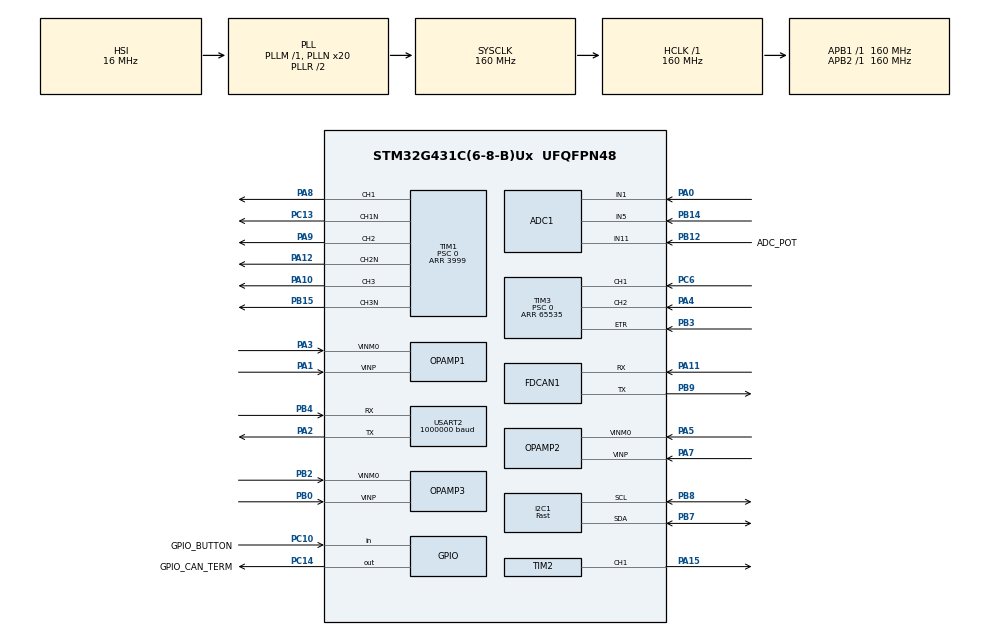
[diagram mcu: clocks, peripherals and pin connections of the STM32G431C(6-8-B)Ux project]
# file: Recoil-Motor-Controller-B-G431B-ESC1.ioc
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ADC1.DMAContinuousRequests=DISABLE
ADC1.EOCSelection=ADC_EOC_SEQ_CONV
ADC1.EnableInjectedConversion=ENABLE
ADC1.EnableRegularConversion=DISABLE
ADC1.ExternalTrigInjecConv=ADC_EXTERNALTRIGINJEC_T1_TRGO
ADC1.InjNumberOfConversion=3
ADC1.InjectedChannel-13\#ChannelInjectedConversion=ADC_CHANNEL_1
ADC1.InjectedChannel-14\#ChannelInjectedConversion=ADC_CHANNEL_11
ADC1.InjectedChannel-8\#ChannelInjectedConversion=ADC_CHANNEL_VOPAMP1
ADC1.InjectedConvMode=None
ADC1.InjectedOffsetNumber-13\#ChannelInjectedConversion=ADC_OFFSET_NONE
ADC1.InjectedOffsetNumber-14\#ChannelInjectedConversion=ADC_OFFSET_NONE
ADC1.InjectedOffsetNumber-8\#ChannelInjectedConversion=ADC_OFFSET_NONE
ADC1.InjectedRank-13\#ChannelInjectedConversion=2
ADC1.InjectedRank-14\#ChannelInjectedConversion=3
ADC1.InjectedRank-8\#ChannelInjectedConversion=1
ADC1.InjectedSamplingTime-13\#ChannelInjectedConversion=ADC_SAMPLETIME_2CYCLES_5
ADC1.InjectedSamplingTime-14\#ChannelInjectedConversion=ADC_SAMPLETIME_2CYCLES_5
ADC1.InjectedSamplingTime-8\#ChannelInjectedConversion=ADC_SAMPLETIME_2CYCLES_5
ADC1.Overrun=ADC_OVR_DATA_OVERWRITTEN
ADC1.Rank1_Channel=ADC_CHANNEL_VOPAMP1
ADC1.Rank2_Channel=ADC_CHANNEL_1
ADC1.Rank3_Channel=ADC_CHANNEL_11
ADC1.master=1
ADC2.DMAContinuousRequests=DISABLE
ADC2.EOCSelection=ADC_EOC_SEQ_CONV
ADC2.EnableInjectedConversion=ENABLE
ADC2.EnableRegularConversion=DISABLE
ADC2.ExternalTrigInjecConv=ADC_EXTERNALTRIGINJEC_T1_TRGO
ADC2.InjNumberOfConversion=2
ADC2.InjectedChannel-4\#ChannelInjectedConversion=ADC_CHANNEL_VOPAMP2
ADC2.InjectedChannel-5\#ChannelInjectedConversion=ADC_CHANNEL_VOPAMP3_ADC2
ADC2.InjectedConvMode=None
ADC2.InjectedOffsetNumber-4\#ChannelInjectedConversion=ADC_OFFSET_NONE
ADC2.InjectedOffsetNumber-5\#ChannelInjectedConversion=ADC_OFFSET_NONE
ADC2.InjectedRank-4\#ChannelInjectedConversion=1
ADC2.InjectedRank-5\#ChannelInjectedConversion=2
ADC2.InjectedSamplingTime-4\#ChannelInjectedConversion=ADC_SAMPLETIME_2CYCLES_5
ADC2.InjectedSamplingTime-5\#ChannelInjectedConversion=ADC_SAMPLETIME_2CYCLES_5
ADC2.Overrun=ADC_OVR_DATA_OVERWRITTEN
FDCAN1.CalculateBaudRateNominal=1000000
FDCAN1.CalculateTimeBitNominal=1000
FDCAN1.CalculateTimeQuantumNominal=100.0
FDCAN1.Mode=FDCAN_MODE_NORMAL
FDCAN1.NominalPrescaler=16
FDCAN1.NominalTimeSeg1=7
FDCAN1.NominalTimeSeg2=2
I2C1.I2C_Speed_Mode=I2C_Fast
I2C1.Timing=0x00F07BFF
Mcu.Family=STM32G4
Mcu.Name=STM32G431C(6-8-B)Ux
Mcu.Package=UFQFPN48
NVIC.FDCAN1_IT0_IRQn=true\:4\:0\:true\:false\:true\:true\:true\:true
NVIC.FDCAN1_IT1_IRQn=true\:4\:0\:true\:false\:true\:true\:true\:true
NVIC.I2C1_EV_IRQn=true\:1\:0\:true\:false\:true\:true\:true\:true
NVIC.PriorityGroup=NVIC_PRIORITYGROUP_4
NVIC.TIM1_UP_TIM16_IRQn=true\:1\:0\:true\:false\:true\:true\:true\:true
NVIC.TIM2_IRQn=true\:0\:0\:true\:false\:true\:true\:true\:true
NVIC.TIM7_IRQn=true\:0\:0\:false\:false\:true\:true\:true\:true
NVIC.TIM8_UP_IRQn=true\:3\:0\:true\:false\:true\:true\:true\:true
OPAMP1.PgaGain=OPAMP_PGA_GAIN_16_OR_MINUS_15
OPAMP2.PgaGain=OPAMP_PGA_GAIN_16_OR_MINUS_15
OPAMP3.PgaGain=OPAMP_PGA_GAIN_16_OR_MINUS_15
PA0.Mode=IN1-Single-Ended
PA0.Signal=ADC1_IN1
PA1.Mode=PGA Internally connected_IO0_BIAS
PA1.Signal=OPAMP1_VINP
PA10.GPIO_PuPd=GPIO_PULLDOWN
PA10.GPIO_Speed=GPIO_SPEED_FREQ_LOW
PA10.Signal=S_TIM1_CH3
PA11.Mode=FDCAN_Activate
PA11.Signal=FDCAN1_RX
PA12.GPIO_PuPd=GPIO_PULLDOWN
PA12.GPIO_Speed=GPIO_SPEED_FREQ_LOW
PA12.Mode=PWM Generation2 CH2 CH2N
PA12.Signal=TIM1_CH2N
PA13.Mode=Serial_Wire
PA13.Signal=SYS_JTMS-SWDIO
PA14.Mode=Serial_Wire
PA14.Signal=SYS_JTCK-SWCLK
PA15.Signal=S_TIM2_CH1
PA2.Mode=Asynchronous
PA2.Signal=USART2_TX
PA3.Mode=PGA Internally connected_IO0_BIAS
PA3.Signal=OPAMP1_VINM0
PA4.Signal=S_TIM3_CH2
PA5.Mode=PGA Internally connected_IO0_BIAS
PA5.Signal=OPAMP2_VINM0
PA7.Mode=PGA Internally connected_IO0_BIAS
PA7.Signal=OPAMP2_VINP
PA8.GPIO_PuPd=GPIO_PULLDOWN
PA8.GPIO_Speed=GPIO_SPEED_FREQ_LOW
PA8.Signal=S_TIM1_CH1
PA9.GPIO_PuPd=GPIO_PULLDOWN
PA9.GPIO_Speed=GPIO_SPEED_FREQ_LOW
PA9.Signal=S_TIM1_CH2
PB0.Mode=PGA Internally connected_IO0_BIAS
PB0.Signal=OPAMP3_VINP
PB12.GPIO_Label=ADC_POT
PB12.Mode=IN11-Single-Ended
PB12.Signal=ADC1_IN11
PB14.Mode=IN5-Single-Ended
PB14.Signal=ADC1_IN5
PB15.GPIO_PuPd=GPIO_PULLDOWN
PB15.GPIO_Speed=GPIO_SPEED_FREQ_LOW
PB15.Mode=PWM Generation3 CH3 CH3N
PB15.Signal=TIM1_CH3N
PB2.Mode=PGA Internally connected_IO0_BIAS
PB2.Signal=OPAMP3_VINM0
PB3.Signal=S_TIM3_ETR
PB4.Mode=Asynchronous
PB4.Signal=USART2_RX
PB7.GPIO_Pu=GPIO_PULLUP
PB7.GPIO_Speed=GPIO_SPEED_FREQ_VERY_HIGH
PB7.Mode=I2C
PB7.Signal=I2C1_SDA
PB8-BOOT0.GPIO_Pu=GPIO_PULLUP
PB8-BOOT0.GPIO_Speed=GPIO_SPEED_FREQ_VERY_HIGH
PB8-BOOT0.Mode=I2C
PB8-BOOT0.Signal=I2C1_SCL
PB9.Mode=FDCAN_Activate
PB9.Signal=FDCAN1_TX
PC10.GPIO_Label=GPIO_BUTTON
PC10.Signal=GPIO_Input
PC13.GPIO_PuPd=GPIO_PULLDOWN
PC13.Mode=PWM Generation1 CH1 CH1N
PC13.Signal=TIM1_CH1N
PC14-OSC32_IN.GPIO_Label=GPIO_CAN_TERM
PC14-OSC32_IN.Signal=GPIO_Output
PC6.Signal=S_TIM3_CH1
PF0-OSC_IN.Mode=HSE-External-Oscillator
PF0-OSC_IN.Signal=RCC_OSC_IN
PF1-OSC_OUT.Mode=HSE-External-Oscillator
PF1-OSC_OUT.Signal=RCC_OSC_OUT
ProjectManager.HeapSize=0x200
ProjectManager.StackSize=0x400
ProjectManager.TargetToolchain=STM32CubeIDE
RCC.ADC12Freq_Value=160000000
RCC.AHBFreq_Value=160000000
RCC.APB1Freq_Value=160000000
RCC.APB1TimFreq_Value=160000000
RCC.APB2Freq_Value=160000000
RCC.APB2TimFreq_Value=160000000
RCC.CortexFreq_Value=160000000
RCC.EXTERNAL_CLOCK_VALUE=12288000
RCC.HCLKFreq_Value=160000000
RCC.HSE_VALUE=8000000
RCC.HSI48_VALUE=48000000
RCC.HSI_VALUE=16000000
RCC.LSE_VALUE=32768
RCC.PLLN=20
RCC.SYSCLKFreq_VALUE=160000000
RCC.SYSCLKSource=RCC_SYSCLKSOURCE_PLLCLK
RCC.USBFreq_Value=160000000
RCC.VCOOutputFreq_Value=320000000
SH.S_TIM1_CH1.0=TIM1_CH1,PWM Generation1 CH1 CH1N
SH.S_TIM1_CH2.0=TIM1_CH2,PWM Generation2 CH2 CH2N
SH.S_TIM1_CH3.0=TIM1_CH3,PWM Generation3 CH3 CH3N
SH.S_TIM2_CH1.0=TIM2_CH1,PWM Generation1 CH1
SH.S_TIM3_CH1.0=TIM3_CH1,Encoder_Interface_w_index
SH.S_TIM3_CH2.0=TIM3_CH2,Encoder_Interface_w_index
SH.S_TIM3_ETR.0=TIM3_ETR,Encoder_Interface_w_index
TIM1.Channel-PWM\ Generation1\ CH1\ CH1N=TIM_CHANNEL_1
TIM1.Channel-PWM\ Generation2\ CH2\ CH2N=TIM_CHANNEL_2
TIM1.Channel-PWM\ Generation3\ CH3\ CH3N=TIM_CHANNEL_3
TIM1.Channel-PWM\ Generation4\ No\ Output=TIM_CHANNEL_4
TIM1.CounterMode=TIM_COUNTERMODE_CENTERALIGNED1
TIM1.DeadTime=128
TIM1.OCNIdleState_1=TIM_OCNIDLESTATE_RESET
TIM1.OCNIdleState_2=TIM_OCNIDLESTATE_RESET
TIM1.OCNIdleState_3=TIM_OCNIDLESTATE_RESET
TIM1.PeriodNoDither=3999
TIM1.Prescaler=0
TIM1.PulseNoDither_4=3998
TIM1.RepetitionCounter=3
TIM1.TIM_MasterOutputTrigger=TIM_TRGO_OC4REF
TIM1.TIM_MasterOutputTrigger2=TIM_TRGO2_RESET
TIM2.Channel-PWM\ Generation1\ CH1=TIM_CHANNEL_1
TIM2.CounterMode=TIM_COUNTERMODE_UP
TIM2.PeriodNoDither=9999
TIM2.Prescaler=15900
TIM2.TIM_MasterOutputTrigger=TIM_TRGO_RESET
TIM3.EncoderMode=TIM_ENCODERMODE_TI12
TIM3.FirstIndexEnable=ENABLE
TIM3.PeriodNoDither=65535
TIM3.Prescaler=0
TIM6.Prescaler=1599
TIM7.PeriodNoDither=9999
TIM7.Prescaler=15999
TIM7.TIM_MasterOutputTrigger=TIM_TRGO_UPDATE
TIM8.PeriodNoDither=1000
TIM8.Prescaler=15999
USART2.BaudRate=1000000
USART2.VirtualMode-Asynchronous=VM_ASYNC
VP_ADC1_OPAMP_INTERNAL1.Mode=IN-OPAMP1
VP_ADC2_OPAMP_INTERNAL2.Mode=IN-OPAMP2
VP_ADC2_OPAMP_INTERNAL3.Mode=IN-OPAMP3
VP_SYS_VS_DBSignals.Mode=DisableDeadBatterySignals
VP_TIM1_VS_ClockSourceINT.Mode=Internal
VP_TIM1_VS_no_output4.Mode=PWM Generation4 No Output
VP_TIM2_VS_ClockSourceINT.Mode=Internal
VP_TIM6_VS_ClockSourceINT.Mode=Enable_Timer
VP_TIM7_VS_ClockSourceINT.Mode=Enable_Timer
VP_TIM8_VS_ClockSourceINT.Mode=Internal
board=custom

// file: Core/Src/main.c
/* USER CODE BEGIN Header */
/**
  ******************************************************************************
  * @file           : main.c
  * @brief          : Main program body
  ******************************************************************************
  * @attention
  *
  * Copyright (c) 2022 STMicroelectronics.
  * All rights reserved.
  *
  * This software is licensed under terms that can be found in the LICENSE file
  * in the root directory of this software component.
  * If no LICENSE file comes with this software, it is provided AS-IS.
  *
  ******************************************************************************
  */
/* USER CODE END Header */
#include "main.h"

ADC_HandleTypeDef hadc1;
ADC_HandleTypeDef hadc2;

FDCAN_HandleTypeDef hfdcan1;

I2C_HandleTypeDef hi2c1;

OPAMP_HandleTypeDef hopamp1;
OPAMP_HandleTypeDef hopamp2;
OPAMP_HandleTypeDef hopamp3;

TIM_HandleTypeDef htim1;
TIM_HandleTypeDef htim2;
TIM_HandleTypeDef htim3;
TIM_HandleTypeDef htim6;
TIM_HandleTypeDef htim7;
TIM_HandleTypeDef htim8;

UART_HandleTypeDef huart2;

void SystemClock_Config(void);
static void MX_GPIO_Init(void);
static void MX_ADC1_Init(void);
static void MX_FDCAN1_Init(void);
static void MX_I2C1_Init(void);
static void MX_OPAMP1_Init(void);
static void MX_OPAMP2_Init(void);
static void MX_OPAMP3_Init(void);
static void MX_TIM1_Init(void);
static void MX_USART2_UART_Init(void);
static void MX_ADC2_Init(void);
static void MX_TIM2_Init(void);
static void MX_TIM6_Init(void);
static void MX_TIM3_Init(void);
static void MX_TIM8_Init(void);
static void MX_TIM7_Init(void);

int main(void)
{

  /* MCU Configuration--------------------------------------------------------*/

  /* Reset of all peripherals, Initializes the Flash interface and the Systick. */
  HAL_Init();

  /* Configure the system clock */
  SystemClock_Config();

  /* Initialize all configured peripherals */
  MX_GPIO_Init();
  MX_ADC1_Init();
  MX_FDCAN1_Init();
  MX_I2C1_Init();
  MX_OPAMP1_Init();
  MX_OPAMP2_Init();
  MX_OPAMP3_Init();
  MX_TIM1_Init();
  MX_USART2_UART_Init();
  MX_ADC2_Init();
  MX_TIM2_Init();
  MX_TIM6_Init();
  MX_TIM3_Init();
  MX_TIM8_Init();
  MX_TIM7_Init();
  /* USER CODE BEGIN 2 */
  APP_init();
  /* USER CODE END 2 */

  /* Infinite loop */
  /* USER CODE BEGIN WHILE */
  while (1)
  {
    APP_main();
    /* USER CODE END WHILE */

  }
}

void SystemClock_Config(void)
{
  RCC_OscInitTypeDef RCC_OscInitStruct = {0};
  RCC_ClkInitTypeDef RCC_ClkInitStruct = {0};

  /** Configure the main internal regulator output voltage
  */
  HAL_PWREx_ControlVoltageScaling(PWR_REGULATOR_VOLTAGE_SCALE1_BOOST);

  /** Initializes the RCC Oscillators according to the specified parameters
  * in the RCC_OscInitTypeDef structure.
  */
  RCC_OscInitStruct.OscillatorType = RCC_OSCILLATORTYPE_HSI;
  RCC_OscInitStruct.HSIState = RCC_HSI_ON;
  RCC_OscInitStruct.HSICalibrationValue = RCC_HSICALIBRATION_DEFAULT;
  RCC_OscInitStruct.PLL.PLLState = RCC_PLL_ON;
  RCC_OscInitStruct.PLL.PLLSource = RCC_PLLSOURCE_HSI;
  RCC_OscInitStruct.PLL.PLLM = RCC_PLLM_DIV1;
  RCC_OscInitStruct.PLL.PLLN = 20;
  RCC_OscInitStruct.PLL.PLLP = RCC_PLLP_DIV2;
  RCC_OscInitStruct.PLL.PLLQ = RCC_PLLQ_DIV2;
  RCC_OscInitStruct.PLL.PLLR = RCC_PLLR_DIV2;
  if (HAL_RCC_OscConfig(&RCC_OscInitStruct) != HAL_OK)
  {
    Error_Handler();
  }

  /** Initializes the CPU, AHB and APB buses clocks
  */
  RCC_ClkInitStruct.ClockType = RCC_CLOCKTYPE_HCLK|RCC_CLOCKTYPE_SYSCLK
                              |RCC_CLOCKTYPE_PCLK1|RCC_CLOCKTYPE_PCLK2;
  RCC_ClkInitStruct.SYSCLKSource = RCC_SYSCLKSOURCE_PLLCLK;
  RCC_ClkInitStruct.AHBCLKDivider = RCC_SYSCLK_DIV1;
  RCC_ClkInitStruct.APB1CLKDivider = RCC_HCLK_DIV1;
  RCC_ClkInitStruct.APB2CLKDivider = RCC_HCLK_DIV1;

  if (HAL_RCC_ClockConfig(&RCC_ClkInitStruct, FLASH_LATENCY_4) != HAL_OK)
  {
    Error_Handler();
  }
}

static void MX_ADC1_Init(void)
{

  ADC_MultiModeTypeDef multimode = {0};
  ADC_InjectionConfTypeDef sConfigInjected = {0};

  /** Common config
  */
  hadc1.Instance = ADC1;
  hadc1.Init.ClockPrescaler = ADC_CLOCK_SYNC_PCLK_DIV4;
  hadc1.Init.Resolution = ADC_RESOLUTION_12B;
  hadc1.Init.DataAlign = ADC_DATAALIGN_RIGHT;
  hadc1.Init.GainCompensation = 0;
  hadc1.Init.ScanConvMode = ADC_SCAN_ENABLE;
  hadc1.Init.EOCSelection = ADC_EOC_SEQ_CONV;
  hadc1.Init.LowPowerAutoWait = DISABLE;
  hadc1.Init.ContinuousConvMode = DISABLE;
  hadc1.Init.NbrOfConversion = 1;
  hadc1.Init.DiscontinuousConvMode = DISABLE;
  hadc1.Init.DMAContinuousRequests = DISABLE;
  hadc1.Init.Overrun = ADC_OVR_DATA_OVERWRITTEN;
  hadc1.Init.OversamplingMode = DISABLE;
  if (HAL_ADC_Init(&hadc1) != HAL_OK)
  {
    Error_Handler();
  }

  /** Configure the ADC multi-mode
  */
  multimode.Mode = ADC_MODE_INDEPENDENT;
  if (HAL_ADCEx_MultiModeConfigChannel(&hadc1, &multimode) != HAL_OK)
  {
    Error_Handler();
  }

  /** Configure Injected Channel
  */
  sConfigInjected.InjectedChannel = ADC_CHANNEL_VOPAMP1;
  sConfigInjected.InjectedRank = ADC_INJECTED_RANK_1;
  sConfigInjected.InjectedSamplingTime = ADC_SAMPLETIME_2CYCLES_5;
  sConfigInjected.InjectedSingleDiff = ADC_SINGLE_ENDED;
  sConfigInjected.InjectedOffsetNumber = ADC_OFFSET_NONE;
  sConfigInjected.InjectedOffset = 0;
  sConfigInjected.InjectedNbrOfConversion = 3;
  sConfigInjected.InjectedDiscontinuousConvMode = DISABLE;
  sConfigInjected.AutoInjectedConv = DISABLE;
  sConfigInjected.QueueInjectedContext = DISABLE;
  sConfigInjected.ExternalTrigInjecConv = ADC_EXTERNALTRIGINJEC_T1_TRGO;
  sConfigInjected.ExternalTrigInjecConvEdge = ADC_EXTERNALTRIGINJECCONV_EDGE_RISING;
  sConfigInjected.InjecOversamplingMode = DISABLE;
  if (HAL_ADCEx_InjectedConfigChannel(&hadc1, &sConfigInjected) != HAL_OK)
  {
    Error_Handler();
  }

  /** Configure Injected Channel
  */
  sConfigInjected.InjectedChannel = ADC_CHANNEL_1;
  sConfigInjected.InjectedRank = ADC_INJECTED_RANK_2;
  if (HAL_ADCEx_InjectedConfigChannel(&hadc1, &sConfigInjected) != HAL_OK)
  {
    Error_Handler();
  }

  /** Configure Injected Channel
  */
  sConfigInjected.InjectedChannel = ADC_CHANNEL_11;
  sConfigInjected.InjectedRank = ADC_INJECTED_RANK_3;
  if (HAL_ADCEx_InjectedConfigChannel(&hadc1, &sConfigInjected) != HAL_OK)
  {
    Error_Handler();
  }

}

static void MX_ADC2_Init(void)
{

  ADC_InjectionConfTypeDef sConfigInjected = {0};

  /** Common config
  */
  hadc2.Instance = ADC2;
  hadc2.Init.ClockPrescaler = ADC_CLOCK_SYNC_PCLK_DIV4;
  hadc2.Init.Resolution = ADC_RESOLUTION_12B;
  hadc2.Init.DataAlign = ADC_DATAALIGN_RIGHT;
  hadc2.Init.GainCompensation = 0;
  hadc2.Init.ScanConvMode = ADC_SCAN_ENABLE;
  hadc2.Init.EOCSelection = ADC_EOC_SEQ_CONV;
  hadc2.Init.LowPowerAutoWait = DISABLE;
  hadc2.Init.ContinuousConvMode = DISABLE;
  hadc2.Init.NbrOfConversion = 1;
  hadc2.Init.DiscontinuousConvMode = DISABLE;
  hadc2.Init.DMAContinuousRequests = DISABLE;
  hadc2.Init.Overrun = ADC_OVR_DATA_OVERWRITTEN;
  hadc2.Init.OversamplingMode = DISABLE;
  if (HAL_ADC_Init(&hadc2) != HAL_OK)
  {
    Error_Handler();
  }

  /** Configure Injected Channel
  */
  sConfigInjected.InjectedChannel = ADC_CHANNEL_VOPAMP2;
  sConfigInjected.InjectedRank = ADC_INJECTED_RANK_1;
  sConfigInjected.InjectedSamplingTime = ADC_SAMPLETIME_2CYCLES_5;
  sConfigInjected.InjectedSingleDiff = ADC_SINGLE_ENDED;
  sConfigInjected.InjectedOffsetNumber = ADC_OFFSET_NONE;
  sConfigInjected.InjectedOffset = 0;
  sConfigInjected.InjectedNbrOfConversion = 2;
  sConfigInjected.InjectedDiscontinuousConvMode = DISABLE;
  sConfigInjected.AutoInjectedConv = DISABLE;
  sConfigInjected.QueueInjectedContext = DISABLE;
  sConfigInjected.ExternalTrigInjecConv = ADC_EXTERNALTRIGINJEC_T1_TRGO;
  sConfigInjected.ExternalTrigInjecConvEdge = ADC_EXTERNALTRIGINJECCONV_EDGE_RISING;
  sConfigInjected.InjecOversamplingMode = DISABLE;
  if (HAL_ADCEx_InjectedConfigChannel(&hadc2, &sConfigInjected) != HAL_OK)
  {
    Error_Handler();
  }

  /** Configure Injected Channel
  */
  sConfigInjected.InjectedChannel = ADC_CHANNEL_VOPAMP3_ADC2;
  sConfigInjected.InjectedRank = ADC_INJECTED_RANK_2;
  if (HAL_ADCEx_InjectedConfigChannel(&hadc2, &sConfigInjected) != HAL_OK)
  {
    Error_Handler();
  }

}

static void MX_FDCAN1_Init(void)
{

  hfdcan1.Instance = FDCAN1;
  hfdcan1.Init.ClockDivider = FDCAN_CLOCK_DIV1;
  hfdcan1.Init.FrameFormat = FDCAN_FRAME_CLASSIC;
  hfdcan1.Init.Mode = FDCAN_MODE_NORMAL;
  hfdcan1.Init.AutoRetransmission = DISABLE;
  hfdcan1.Init.TransmitPause = DISABLE;
  hfdcan1.Init.ProtocolException = DISABLE;
  hfdcan1.Init.NominalPrescaler = 16;
  hfdcan1.Init.NominalSyncJumpWidth = 1;
  hfdcan1.Init.NominalTimeSeg1 = 7;
  hfdcan1.Init.NominalTimeSeg2 = 2;
  hfdcan1.Init.DataPrescaler = 1;
  hfdcan1.Init.DataSyncJumpWidth = 1;
  hfdcan1.Init.DataTimeSeg1 = 1;
  hfdcan1.Init.DataTimeSeg2 = 1;
  hfdcan1.Init.StdFiltersNbr = 0;
  hfdcan1.Init.ExtFiltersNbr = 0;
  hfdcan1.Init.TxFifoQueueMode = FDCAN_TX_FIFO_OPERATION;
  if (HAL_FDCAN_Init(&hfdcan1) != HAL_OK)
  {
    Error_Handler();
  }

}

static void MX_I2C1_Init(void)
{

  hi2c1.Instance = I2C1;
  hi2c1.Init.Timing = 0x00F07BFF;
  hi2c1.Init.OwnAddress1 = 0;
  hi2c1.Init.AddressingMode = I2C_ADDRESSINGMODE_7BIT;
  hi2c1.Init.DualAddressMode = I2C_DUALADDRESS_DISABLE;
  hi2c1.Init.OwnAddress2 = 0;
  hi2c1.Init.OwnAddress2Masks = I2C_OA2_NOMASK;
  hi2c1.Init.GeneralCallMode = I2C_GENERALCALL_DISABLE;
  hi2c1.Init.NoStretchMode = I2C_NOSTRETCH_DISABLE;
  if (HAL_I2C_Init(&hi2c1) != HAL_OK)
  {
    Error_Handler();
  }

  /** Configure Analogue filter
  */
  if (HAL_I2CEx_ConfigAnalogFilter(&hi2c1, I2C_ANALOGFILTER_ENABLE) != HAL_OK)
  {
    Error_Handler();
  }

  /** Configure Digital filter
  */
  if (HAL_I2CEx_ConfigDigitalFilter(&hi2c1, 0) != HAL_OK)
  {
    Error_Handler();
  }

}

static void MX_OPAMP1_Init(void)
{

  hopamp1.Instance = OPAMP1;
  hopamp1.Init.PowerMode = OPAMP_POWERMODE_NORMALSPEED;
  hopamp1.Init.Mode = OPAMP_PGA_MODE;
  hopamp1.Init.NonInvertingInput = OPAMP_NONINVERTINGINPUT_IO0;
  hopamp1.Init.InternalOutput = ENABLE;
  hopamp1.Init.TimerControlledMuxmode = OPAMP_TIMERCONTROLLEDMUXMODE_DISABLE;
  hopamp1.Init.PgaConnect = OPAMP_PGA_CONNECT_INVERTINGINPUT_IO0_BIAS;
  hopamp1.Init.PgaGain = OPAMP_PGA_GAIN_16_OR_MINUS_15;
  hopamp1.Init.UserTrimming = OPAMP_TRIMMING_FACTORY;
  if (HAL_OPAMP_Init(&hopamp1) != HAL_OK)
  {
    Error_Handler();
  }

}

static void MX_OPAMP2_Init(void)
{

  hopamp2.Instance = OPAMP2;
  hopamp2.Init.PowerMode = OPAMP_POWERMODE_NORMALSPEED;
  hopamp2.Init.Mode = OPAMP_PGA_MODE;
  hopamp2.Init.NonInvertingInput = OPAMP_NONINVERTINGINPUT_IO0;
  hopamp2.Init.InternalOutput = ENABLE;
  hopamp2.Init.TimerControlledMuxmode = OPAMP_TIMERCONTROLLEDMUXMODE_DISABLE;
  hopamp2.Init.PgaConnect = OPAMP_PGA_CONNECT_INVERTINGINPUT_IO0_BIAS;
  hopamp2.Init.PgaGain = OPAMP_PGA_GAIN_16_OR_MINUS_15;
  hopamp2.Init.UserTrimming = OPAMP_TRIMMING_FACTORY;
  if (HAL_OPAMP_Init(&hopamp2) != HAL_OK)
  {
    Error_Handler();
  }

}

static void MX_OPAMP3_Init(void)
{

  hopamp3.Instance = OPAMP3;
  hopamp3.Init.PowerMode = OPAMP_POWERMODE_NORMALSPEED;
  hopamp3.Init.Mode = OPAMP_PGA_MODE;
  hopamp3.Init.NonInvertingInput = OPAMP_NONINVERTINGINPUT_IO0;
  hopamp3.Init.InternalOutput = ENABLE;
  hopamp3.Init.TimerControlledMuxmode = OPAMP_TIMERCONTROLLEDMUXMODE_DISABLE;
  hopamp3.Init.PgaConnect = OPAMP_PGA_CONNECT_INVERTINGINPUT_IO0_BIAS;
  hopamp3.Init.PgaGain = OPAMP_PGA_GAIN_16_OR_MINUS_15;
  hopamp3.Init.UserTrimming = OPAMP_TRIMMING_FACTORY;
  if (HAL_OPAMP_Init(&hopamp3) != HAL_OK)
  {
    Error_Handler();
  }

}

static void MX_TIM1_Init(void)
{

  TIM_ClockConfigTypeDef sClockSourceConfig = {0};
  TIM_MasterConfigTypeDef sMasterConfig = {0};
  TIM_OC_InitTypeDef sConfigOC = {0};
  TIM_BreakDeadTimeConfigTypeDef sBreakDeadTimeConfig = {0};

  htim1.Instance = TIM1;
  htim1.Init.Prescaler = 0;
  htim1.Init.CounterMode = TIM_COUNTERMODE_CENTERALIGNED1;
  htim1.Init.Period = 3999;
  htim1.Init.ClockDivision = TIM_CLOCKDIVISION_DIV1;
  htim1.Init.RepetitionCounter = 3;
  htim1.Init.AutoReloadPreload = TIM_AUTORELOAD_PRELOAD_DISABLE;
  if (HAL_TIM_Base_Init(&htim1) != HAL_OK)
  {
    Error_Handler();
  }
  sClockSourceConfig.ClockSource = TIM_CLOCKSOURCE_INTERNAL;
  if (HAL_TIM_ConfigClockSource(&htim1, &sClockSourceConfig) != HAL_OK)
  {
    Error_Handler();
  }
  if (HAL_TIM_PWM_Init(&htim1) != HAL_OK)
  {
    Error_Handler();
  }
  sMasterConfig.MasterOutputTrigger = TIM_TRGO_OC4REF;
  sMasterConfig.MasterOutputTrigger2 = TIM_TRGO2_RESET;
  sMasterConfig.MasterSlaveMode = TIM_MASTERSLAVEMODE_DISABLE;
  if (HAL_TIMEx_MasterConfigSynchronization(&htim1, &sMasterConfig) != HAL_OK)
  {
    Error_Handler();
  }
  sConfigOC.OCMode = TIM_OCMODE_PWM1;
  sConfigOC.Pulse = 0;
  sConfigOC.OCPolarity = TIM_OCPOLARITY_HIGH;
  sConfigOC.OCNPolarity = TIM_OCNPOLARITY_HIGH;
  sConfigOC.OCFastMode = TIM_OCFAST_DISABLE;
  sConfigOC.OCIdleState = TIM_OCIDLESTATE_RESET;
  sConfigOC.OCNIdleState = TIM_OCNIDLESTATE_RESET;
  if (HAL_TIM_PWM_ConfigChannel(&htim1, &sConfigOC, TIM_CHANNEL_1) != HAL_OK)
  {
    Error_Handler();
  }
  if (HAL_TIM_PWM_ConfigChannel(&htim1, &sConfigOC, TIM_CHANNEL_2) != HAL_OK)
  {
    Error_Handler();
  }
  if (HAL_TIM_PWM_ConfigChannel(&htim1, &sConfigOC, TIM_CHANNEL_3) != HAL_OK)
  {
    Error_Handler();
  }
  sConfigOC.Pulse = 3998;
  if (HAL_TIM_PWM_ConfigChannel(&htim1, &sConfigOC, TIM_CHANNEL_4) != HAL_OK)
  {
    Error_Handler();
  }
  sBreakDeadTimeConfig.OffStateRunMode = TIM_OSSR_DISABLE;
  sBreakDeadTimeConfig.OffStateIDLEMode = TIM_OSSI_DISABLE;
  sBreakDeadTimeConfig.LockLevel = TIM_LOCKLEVEL_OFF;
  sBreakDeadTimeConfig.DeadTime = 128;
  sBreakDeadTimeConfig.BreakState = TIM_BREAK_DISABLE;
  sBreakDeadTimeConfig.BreakPolarity = TIM_BREAKPOLARITY_HIGH;
  sBreakDeadTimeConfig.BreakFilter = 0;
  sBreakDeadTimeConfig.BreakAFMode = TIM_BREAK_AFMODE_INPUT;
  sBreakDeadTimeConfig.Break2State = TIM_BREAK2_DISABLE;
  sBreakDeadTimeConfig.Break2Polarity = TIM_BREAK2POLARITY_HIGH;
  sBreakDeadTimeConfig.Break2Filter = 0;
  sBreakDeadTimeConfig.Break2AFMode = TIM_BREAK_AFMODE_INPUT;
  sBreakDeadTimeConfig.AutomaticOutput = TIM_AUTOMATICOUTPUT_DISABLE;
  if (HAL_TIMEx_ConfigBreakDeadTime(&htim1, &sBreakDeadTimeConfig) != HAL_OK)
  {
    Error_Handler();
  }
  HAL_TIM_MspPostInit(&htim1);

}

static void MX_TIM2_Init(void)
{

  TIM_ClockConfigTypeDef sClockSourceConfig = {0};
  TIM_MasterConfigTypeDef sMasterConfig = {0};
  TIM_OC_InitTypeDef sConfigOC = {0};

  htim2.Instance = TIM2;
  htim2.Init.Prescaler = 15900;
  htim2.Init.CounterMode = TIM_COUNTERMODE_UP;
  htim2.Init.Period = 9999;
  htim2.Init.ClockDivision = TIM_CLOCKDIVISION_DIV1;
  htim2.Init.AutoReloadPreload = TIM_AUTORELOAD_PRELOAD_DISABLE;
  if (HAL_TIM_Base_Init(&htim2) != HAL_OK)
  {
    Error_Handler();
  }
  sClockSourceConfig.ClockSource = TIM_CLOCKSOURCE_INTERNAL;
  if (HAL_TIM_ConfigClockSource(&htim2, &sClockSourceConfig) != HAL_OK)
  {
    Error_Handler();
  }
  if (HAL_TIM_PWM_Init(&htim2) != HAL_OK)
  {
    Error_Handler();
  }
  sMasterConfig.MasterOutputTrigger = TIM_TRGO_RESET;
  sMasterConfig.MasterSlaveMode = TIM_MASTERSLAVEMODE_DISABLE;
  if (HAL_TIMEx_MasterConfigSynchronization(&htim2, &sMasterConfig) != HAL_OK)
  {
    Error_Handler();
  }
  sConfigOC.OCMode = TIM_OCMODE_PWM1;
  sConfigOC.Pulse = 0;
  sConfigOC.OCPolarity = TIM_OCPOLARITY_HIGH;
  sConfigOC.OCFastMode = TIM_OCFAST_DISABLE;
  if (HAL_TIM_PWM_ConfigChannel(&htim2, &sConfigOC, TIM_CHANNEL_1) != HAL_OK)
  {
    Error_Handler();
  }
  HAL_TIM_MspPostInit(&htim2);

}

static void MX_TIM3_Init(void)
{

  TIM_Encoder_InitTypeDef sConfig = {0};
  TIM_MasterConfigTypeDef sMasterConfig = {0};
  TIMEx_EncoderIndexConfigTypeDef sEncoderIndexConfig = {0};

  htim3.Instance = TIM3;
  htim3.Init.Prescaler = 0;
  htim3.Init.CounterMode = TIM_COUNTERMODE_UP;
  htim3.Init.Period = 65535;
  htim3.Init.ClockDivision = TIM_CLOCKDIVISION_DIV1;
  htim3.Init.AutoReloadPreload = TIM_AUTORELOAD_PRELOAD_DISABLE;
  sConfig.EncoderMode = TIM_ENCODERMODE_TI12;
  sConfig.IC1Polarity = TIM_ICPOLARITY_RISING;
  sConfig.IC1Selection = TIM_ICSELECTION_DIRECTTI;
  sConfig.IC1Prescaler = TIM_ICPSC_DIV1;
  sConfig.IC1Filter = 0;
  sConfig.IC2Polarity = TIM_ICPOLARITY_RISING;
  sConfig.IC2Selection = TIM_ICSELECTION_DIRECTTI;
  sConfig.IC2Prescaler = TIM_ICPSC_DIV1;
  sConfig.IC2Filter = 0;
  if (HAL_TIM_Encoder_Init(&htim3, &sConfig) != HAL_OK)
  {
    Error_Handler();
  }
  sMasterConfig.MasterOutputTrigger = TIM_TRGO_RESET;
  sMasterConfig.MasterSlaveMode = TIM_MASTERSLAVEMODE_DISABLE;
  if (HAL_TIMEx_MasterConfigSynchronization(&htim3, &sMasterConfig) != HAL_OK)
  {
    Error_Handler();
  }
  sEncoderIndexConfig.Polarity = TIM_ENCODERINDEX_POLARITY_NONINVERTED;
  sEncoderIndexConfig.Prescaler = TIM_ENCODERINDEX_PRESCALER_DIV1;
  sEncoderIndexConfig.Filter = 0;
  sEncoderIndexConfig.FirstIndexEnable = ENABLE;
  sEncoderIndexConfig.Position = TIM_ENCODERINDEX_POSITION_00;
  sEncoderIndexConfig.Direction = TIM_ENCODERINDEX_DIRECTION_UP_DOWN;
  if (HAL_TIMEx_ConfigEncoderIndex(&htim3, &sEncoderIndexConfig) != HAL_OK)
  {
    Error_Handler();
  }

}

static void MX_TIM6_Init(void)
{

  TIM_MasterConfigTypeDef sMasterConfig = {0};

  htim6.Instance = TIM6;
  htim6.Init.Prescaler = 1599;
  htim6.Init.CounterMode = TIM_COUNTERMODE_UP;
  htim6.Init.Period = 65535;
  htim6.Init.AutoReloadPreload = TIM_AUTORELOAD_PRELOAD_DISABLE;
  if (HAL_TIM_Base_Init(&htim6) != HAL_OK)
  {
    Error_Handler();
  }
  sMasterConfig.MasterOutputTrigger = TIM_TRGO_RESET;
  sMasterConfig.MasterSlaveMode = TIM_MASTERSLAVEMODE_DISABLE;
  if (HAL_TIMEx_MasterConfigSynchronization(&htim6, &sMasterConfig) != HAL_OK)
  {
    Error_Handler();
  }

}

static void MX_TIM7_Init(void)
{

  TIM_MasterConfigTypeDef sMasterConfig = {0};

  htim7.Instance = TIM7;
  htim7.Init.Prescaler = 15999;
  htim7.Init.CounterMode = TIM_COUNTERMODE_UP;
  htim7.Init.Period = 9999;
  htim7.Init.AutoReloadPreload = TIM_AUTORELOAD_PRELOAD_DISABLE;
  if (HAL_TIM_Base_Init(&htim7) != HAL_OK)
  {
    Error_Handler();
  }
  sMasterConfig.MasterOutputTrigger = TIM_TRGO_UPDATE;
  sMasterConfig.MasterSlaveMode = TIM_MASTERSLAVEMODE_DISABLE;
  if (HAL_TIMEx_MasterConfigSynchronization(&htim7, &sMasterConfig) != HAL_OK)
  {
    Error_Handler();
  }

}

static void MX_TIM8_Init(void)
{

  TIM_ClockConfigTypeDef sClockSourceConfig = {0};
  TIM_MasterConfigTypeDef sMasterConfig = {0};

  htim8.Instance = TIM8;
  htim8.Init.Prescaler = 15999;
  htim8.Init.CounterMode = TIM_COUNTERMODE_UP;
  htim8.Init.Period = 1000;
  htim8.Init.ClockDivision = TIM_CLOCKDIVISION_DIV1;
  htim8.Init.RepetitionCounter = 0;
  htim8.Init.AutoReloadPreload = TIM_AUTORELOAD_PRELOAD_DISABLE;
  if (HAL_TIM_Base_Init(&htim8) != HAL_OK)
  {
    Error_Handler();
  }
  sClockSourceConfig.ClockSource = TIM_CLOCKSOURCE_INTERNAL;
  if (HAL_TIM_ConfigClockSource(&htim8, &sClockSourceConfig) != HAL_OK)
  {
    Error_Handler();
  }
  sMasterConfig.MasterOutputTrigger = TIM_TRGO_RESET;
  sMasterConfig.MasterOutputTrigger2 = TIM_TRGO2_RESET;
  sMasterConfig.MasterSlaveMode = TIM_MASTERSLAVEMODE_DISABLE;
  if (HAL_TIMEx_MasterConfigSynchronization(&htim8, &sMasterConfig) != HAL_OK)
  {
    Error_Handler();
  }

}

static void MX_USART2_UART_Init(void)
{

  huart2.Instance = USART2;
  huart2.Init.BaudRate = 1000000;
  huart2.Init.WordLength = UART_WORDLENGTH_8B;
  huart2.Init.StopBits = UART_STOPBITS_1;
  huart2.Init.Parity = UART_PARITY_NONE;
  huart2.Init.Mode = UART_MODE_TX_RX;
  huart2.Init.HwFlowCtl = UART_HWCONTROL_NONE;
  huart2.Init.OverSampling = UART_OVERSAMPLING_16;
  huart2.Init.OneBitSampling = UART_ONE_BIT_SAMPLE_DISABLE;
  huart2.Init.ClockPrescaler = UART_PRESCALER_DIV1;
  huart2.AdvancedInit.AdvFeatureInit = UART_ADVFEATURE_NO_INIT;
  if (HAL_UART_Init(&huart2) != HAL_OK)
  {
    Error_Handler();
  }
  if (HAL_UARTEx_SetTxFifoThreshold(&huart2, UART_TXFIFO_THRESHOLD_1_8) != HAL_OK)
  {
    Error_Handler();
  }
  if (HAL_UARTEx_SetRxFifoThreshold(&huart2, UART_RXFIFO_THRESHOLD_1_8) != HAL_OK)
  {
    Error_Handler();
  }
  if (HAL_UARTEx_DisableFifoMode(&huart2) != HAL_OK)
  {
    Error_Handler();
  }

}

static void MX_GPIO_Init(void)
{
  GPIO_InitTypeDef GPIO_InitStruct = {0};

  /* GPIO Ports Clock Enable */
  __HAL_RCC_GPIOC_CLK_ENABLE();
  __HAL_RCC_GPIOF_CLK_ENABLE();
  __HAL_RCC_GPIOA_CLK_ENABLE();
  __HAL_RCC_GPIOB_CLK_ENABLE();

  /*Configure GPIO pin Output Level */
  HAL_GPIO_WritePin(GPIO_CAN_TERM_GPIO_Port, GPIO_CAN_TERM_Pin, GPIO_PIN_RESET);

  /*Configure GPIO pin : GPIO_CAN_TERM_Pin */
  GPIO_InitStruct.Pin = GPIO_CAN_TERM_Pin;
  GPIO_InitStruct.Mode = GPIO_MODE_OUTPUT_PP;
  GPIO_InitStruct.Pull = GPIO_NOPULL;
  GPIO_InitStruct.Speed = GPIO_SPEED_FREQ_LOW;
  HAL_GPIO_Init(GPIO_CAN_TERM_GPIO_Port, &GPIO_InitStruct);

  /*Configure GPIO pin : GPIO_BUTTON_Pin */
  GPIO_InitStruct.Pin = GPIO_BUTTON_Pin;
  GPIO_InitStruct.Mode = GPIO_MODE_INPUT;
  GPIO_InitStruct.Pull = GPIO_NOPULL;
  HAL_GPIO_Init(GPIO_BUTTON_GPIO_Port, &GPIO_InitStruct);

}

void Error_Handler(void)
{
  __disable_irq();
  while (1)
  {
  }
}
